AUTOSAR XML (schema 4-3-0)
package /Comp_FDC_ARPkg
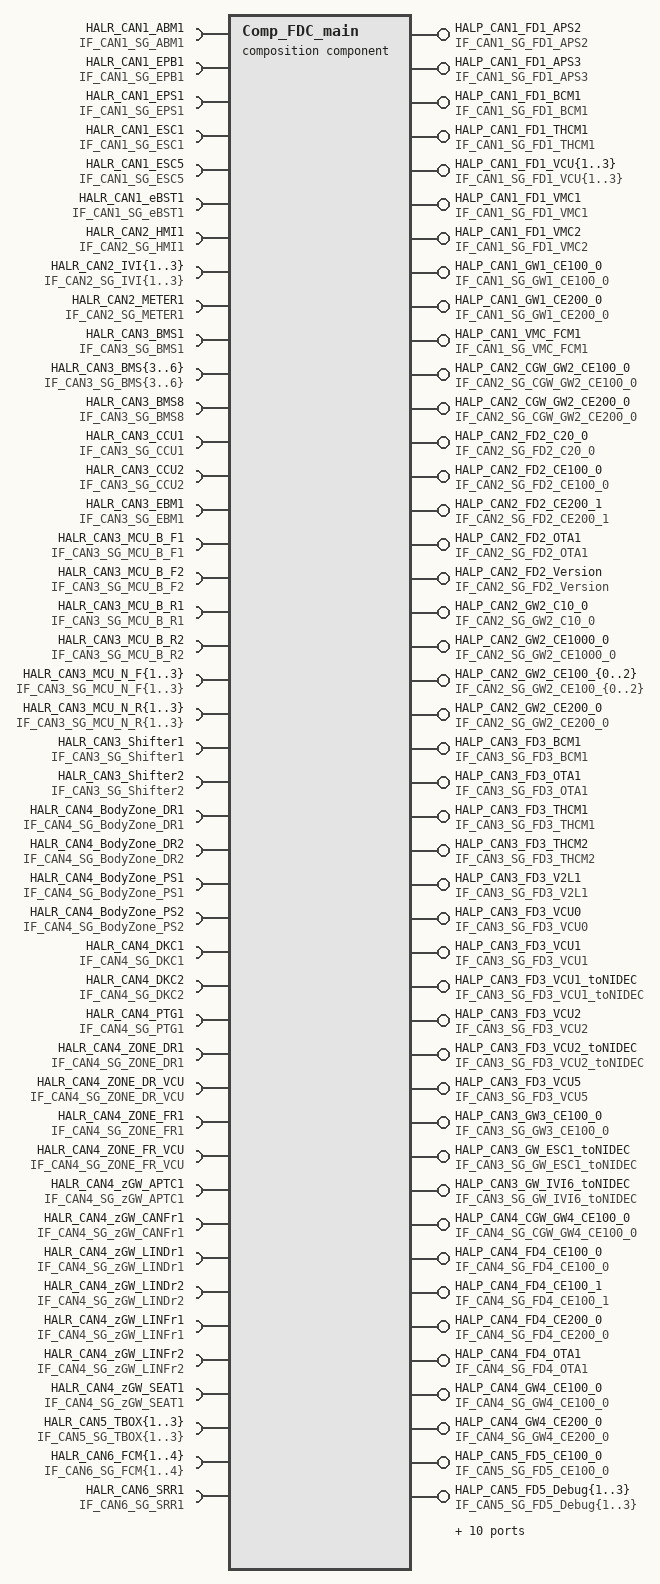
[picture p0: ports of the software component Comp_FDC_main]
  composition sw component type Comp_FDC_main
    58 x require port:
      HALR_CAN1_ABM1: nonqueued-receiver-com-spec{data-element=CAN1_SG_ABM1, handle-out-of-range=DEFAULT, enable-update=true, init-value=constant-reference=Init_CAN1_SG_ABM1}, required-interface=IF_CAN1_SG_ABM1
      HALR_CAN1_EPB1: nonqueued-receiver-com-spec{data-element=CAN1_SG_EPB1, handle-out-of-range=DEFAULT, enable-update=true, init-value=constant-reference=Init_CAN1_SG_EPB1}, required-interface=IF_CAN1_SG_EPB1
      HALR_CAN1_EPS1: nonqueued-receiver-com-spec{data-element=CAN1_SG_EPS1, handle-out-of-range=DEFAULT, enable-update=true, init-value=constant-reference=Init_CAN1_SG_EPS1}, required-interface=IF_CAN1_SG_EPS1
      HALR_CAN1_ESC1: nonqueued-receiver-com-spec{data-element=CAN1_SG_ESC1, handle-out-of-range=DEFAULT, enable-update=true, init-value=constant-reference=Init_CAN1_SG_ESC1}, required-interface=IF_CAN1_SG_ESC1
      HALR_CAN1_ESC5: nonqueued-receiver-com-spec{data-element=CAN1_SG_ESC5, handle-out-of-range=DEFAULT, enable-update=true, init-value=constant-reference=Init_CAN1_SG_ESC5}, required-interface=IF_CAN1_SG_ESC5
      HALR_CAN1_eBST1: nonqueued-receiver-com-spec{data-element=CAN1_SG_eBST1, handle-out-of-range=DEFAULT, enable-update=true, init-value=constant-reference=Init_CAN1_SG_eBST1}, required-interface=IF_CAN1_SG_eBST1
      HALR_CAN2_HMI1: nonqueued-receiver-com-spec{data-element=CAN2_SG_HMI1, handle-out-of-range=DEFAULT, enable-update=true, init-value=constant-reference=Init_CAN2_SG_HMI1}, required-interface=IF_CAN2_SG_HMI1
      HALR_CAN2_IVI{1..3}: nonqueued-receiver-com-spec{data-element=CAN2_SG_IVI{1..3}, handle-out-of-range=DEFAULT, enable-update=true, init-value=constant-reference=Init_CAN2_SG_IVI{1..3}}, required-interface=IF_CAN2_SG_IVI{1..3}
      HALR_CAN2_METER1: nonqueued-receiver-com-spec{data-element=CAN2_SG_METER1, handle-out-of-range=DEFAULT, enable-update=true, init-value=constant-reference=Init_CAN2_SG_METER1}, required-interface=IF_CAN2_SG_METER1
      HALR_CAN3_BMS1: nonqueued-receiver-com-spec{data-element=CAN3_SG_BMS1, handle-out-of-range=DEFAULT, enable-update=true, init-value=constant-reference=Init_CAN3_SG_BMS1}, required-interface=IF_CAN3_SG_BMS1
      HALR_CAN3_BMS{3..6}: nonqueued-receiver-com-spec{data-element=CAN3_SG_BMS{3..6}, handle-out-of-range=DEFAULT, enable-update=true, init-value=constant-reference=Init_CAN3_SG_BMS{3..6}}, required-interface=IF_CAN3_SG_BMS{3..6}
      HALR_CAN3_BMS8: nonqueued-receiver-com-spec{data-element=CAN3_SG_BMS8, handle-out-of-range=DEFAULT, enable-update=true, init-value=constant-reference=Init_CAN3_SG_BMS8}, required-interface=IF_CAN3_SG_BMS8
      HALR_CAN3_CCU1: nonqueued-receiver-com-spec{data-element=CAN3_SG_CCU1, handle-out-of-range=DEFAULT, enable-update=true, init-value=constant-reference=Init_CAN3_SG_CCU1}, required-interface=IF_CAN3_SG_CCU1
      HALR_CAN3_CCU2: nonqueued-receiver-com-spec{data-element=CAN3_SG_CCU2, handle-out-of-range=DEFAULT, enable-update=true, init-value=constant-reference=Init_CAN3_SG_CCU2}, required-interface=IF_CAN3_SG_CCU2
      HALR_CAN3_EBM1: nonqueued-receiver-com-spec{data-element=CAN3_SG_EBM1, handle-out-of-range=DEFAULT, enable-update=true, init-value=constant-reference=Init_CAN3_SG_EBM1}, required-interface=IF_CAN3_SG_EBM1
      HALR_CAN3_MCU_B_F1: nonqueued-receiver-com-spec{data-element=CAN3_SG_MCU_B_F1, handle-out-of-range=DEFAULT, enable-update=true, init-value=constant-reference=Init_CAN3_SG_MCU_B_F1}, required-interface=IF_CAN3_SG_MCU_B_F1
      HALR_CAN3_MCU_B_F2: nonqueued-receiver-com-spec{data-element=CAN3_SG_MCU_B_F2, handle-out-of-range=DEFAULT, enable-update=true, init-value=constant-reference=Init_CAN3_SG_MCU_B_F2}, required-interface=IF_CAN3_SG_MCU_B_F2
      HALR_CAN3_MCU_B_R1: nonqueued-receiver-com-spec{data-element=CAN3_SG_MCU_B_R1, handle-out-of-range=DEFAULT, enable-update=true, init-value=constant-reference=Init_CAN3_SG_MCU_B_R1}, required-interface=IF_CAN3_SG_MCU_B_R1
      HALR_CAN3_MCU_B_R2: nonqueued-receiver-com-spec{data-element=CAN3_SG_MCU_B_R2, handle-out-of-range=DEFAULT, enable-update=true, init-value=constant-reference=Init_CAN3_SG_MCU_B_R2}, required-interface=IF_CAN3_SG_MCU_B_R2
      HALR_CAN3_MCU_N_F{1..3}: nonqueued-receiver-com-spec{data-element=CAN3_SG_MCU_N_F{1..3}, handle-out-of-range=DEFAULT, enable-update=true, init-value=constant-reference=Init_CAN3_SG_MCU_N_F{1..3}}, required-interface=IF_CAN3_SG_MCU_N_F{1..3}
      HALR_CAN3_MCU_N_R{1..3}: nonqueued-receiver-com-spec{data-element=CAN3_SG_MCU_N_R{1..3}, handle-out-of-range=DEFAULT, enable-update=true, init-value=constant-reference=Init_CAN3_SG_MCU_N_R{1..3}}, required-interface=IF_CAN3_SG_MCU_N_R{1..3}
      HALR_CAN3_Shifter1: nonqueued-receiver-com-spec{data-element=CAN3_SG_Shifter1, handle-out-of-range=DEFAULT, enable-update=true, init-value=constant-reference=Init_CAN3_SG_Shifter1}, required-interface=IF_CAN3_SG_Shifter1
      HALR_CAN3_Shifter2: nonqueued-receiver-com-spec{data-element=CAN3_SG_Shifter2, handle-out-of-range=DEFAULT, enable-update=true, init-value=constant-reference=Init_CAN3_SG_Shifter2}, required-interface=IF_CAN3_SG_Shifter2
      HALR_CAN4_BodyZone_DR1: nonqueued-receiver-com-spec{data-element=CAN4_SG_BodyZone_DR1, handle-out-of-range=DEFAULT, enable-update=true, init-value=constant-reference=Init_CAN4_SG_BodyZone_DR1}, required-interface=IF_CAN4_SG_BodyZone_DR1
      HALR_CAN4_BodyZone_DR2: nonqueued-receiver-com-spec{data-element=CAN4_SG_BodyZone_DR2, handle-out-of-range=DEFAULT, enable-update=true, init-value=constant-reference=Init_CAN4_SG_BodyZone_DR2}, required-interface=IF_CAN4_SG_BodyZone_DR2
      HALR_CAN4_BodyZone_PS1: nonqueued-receiver-com-spec{data-element=CAN4_SG_BodyZone_PS1, handle-out-of-range=DEFAULT, enable-update=true, init-value=constant-reference=Init_CAN4_SG_BodyZone_PS1}, required-interface=IF_CAN4_SG_BodyZone_PS1
      HALR_CAN4_BodyZone_PS2: nonqueued-receiver-com-spec{data-element=CAN4_SG_BodyZone_PS2, handle-out-of-range=DEFAULT, enable-update=true, init-value=constant-reference=Init_CAN4_SG_BodyZone_PS2}, required-interface=IF_CAN4_SG_BodyZone_PS2
      HALR_CAN4_DKC1: nonqueued-receiver-com-spec{data-element=CAN4_SG_DKC1, handle-out-of-range=DEFAULT, enable-update=true, init-value=constant-reference=Init_CAN4_SG_DKC1}, required-interface=IF_CAN4_SG_DKC1
      HALR_CAN4_DKC2: nonqueued-receiver-com-spec{data-element=CAN4_SG_DKC2, handle-out-of-range=DEFAULT, enable-update=true, init-value=constant-reference=Init_CAN4_SG_DKC2}, required-interface=IF_CAN4_SG_DKC2
      HALR_CAN4_PTG1: nonqueued-receiver-com-spec{data-element=CAN4_SG_PTG1, handle-out-of-range=DEFAULT, enable-update=true, init-value=constant-reference=Init_CAN4_SG_PTG1}, required-interface=IF_CAN4_SG_PTG1
      HALR_CAN4_ZONE_DR1: nonqueued-receiver-com-spec{data-element=CAN4_SG_ZONE_DR1, handle-out-of-range=DEFAULT, enable-update=true, init-value=constant-reference=Init_CAN4_SG_ZONE_DR1}, required-interface=IF_CAN4_SG_ZONE_DR1
      HALR_CAN4_ZONE_DR_VCU: nonqueued-receiver-com-spec{data-element=CAN4_SG_ZONE_DR_VCU, handle-out-of-range=DEFAULT, enable-update=true, init-value=constant-reference=Init_CAN4_SG_ZONE_DR_VCU}, required-interface=IF_CAN4_SG_ZONE_DR_VCU
      HALR_CAN4_ZONE_FR1: nonqueued-receiver-com-spec{data-element=CAN4_SG_ZONE_FR1, handle-out-of-range=DEFAULT, enable-update=true, init-value=constant-reference=Init_CAN4_SG_ZONE_FR1}, required-interface=IF_CAN4_SG_ZONE_FR1
      HALR_CAN4_ZONE_FR_VCU: nonqueued-receiver-com-spec{data-element=CAN4_SG_ZONE_FR_VCU, handle-out-of-range=DEFAULT, enable-update=true, init-value=constant-reference=Init_CAN4_SG_ZONE_FR_VCU}, required-interface=IF_CAN4_SG_ZONE_FR_VCU
      HALR_CAN4_zGW_APTC1: nonqueued-receiver-com-spec{data-element=CAN4_SG_zGW_APTC1, handle-out-of-range=DEFAULT, enable-update=true, init-value=constant-reference=Init_CAN4_SG_zGW_APTC1}, required-interface=IF_CAN4_SG_zGW_APTC1
      HALR_CAN4_zGW_CANFr1: nonqueued-receiver-com-spec{data-element=CAN4_SG_zGW_CANFr1, handle-out-of-range=DEFAULT, enable-update=true, init-value=constant-reference=Init_CAN4_SG_zGW_CANFr1}, required-interface=IF_CAN4_SG_zGW_CANFr1
      HALR_CAN4_zGW_LINDr1: nonqueued-receiver-com-spec{data-element=CAN4_SG_zGW_LINDr1, handle-out-of-range=DEFAULT, enable-update=true, init-value=constant-reference=Init_CAN4_SG_zGW_LINDr1}, required-interface=IF_CAN4_SG_zGW_LINDr1
      HALR_CAN4_zGW_LINDr2: nonqueued-receiver-com-spec{data-element=CAN4_SG_zGW_LINDr2, handle-out-of-range=DEFAULT, enable-update=true, init-value=constant-reference=Init_CAN4_SG_zGW_LINDr2}, required-interface=IF_CAN4_SG_zGW_LINDr2
      HALR_CAN4_zGW_LINFr1: nonqueued-receiver-com-spec{data-element=CAN4_SG_zGW_LINFr1, handle-out-of-range=DEFAULT, enable-update=true, init-value=constant-reference=Init_CAN4_SG_zGW_LINFr1}, required-interface=IF_CAN4_SG_zGW_LINFr1
      HALR_CAN4_zGW_LINFr2: nonqueued-receiver-com-spec{data-element=CAN4_SG_zGW_LINFr2, handle-out-of-range=DEFAULT, enable-update=true, init-value=constant-reference=Init_CAN4_SG_zGW_LINFr2}, required-interface=IF_CAN4_SG_zGW_LINFr2
      HALR_CAN4_zGW_SEAT1: nonqueued-receiver-com-spec{data-element=CAN4_SG_zGW_SEAT1, handle-out-of-range=DEFAULT, enable-update=true, init-value=constant-reference=Init_CAN4_SG_zGW_SEAT1}, required-interface=IF_CAN4_SG_zGW_SEAT1
      HALR_CAN5_TBOX{1..3}: nonqueued-receiver-com-spec{data-element=CAN5_SG_TBOX{1..3}, handle-out-of-range=DEFAULT, enable-update=true, init-value=constant-reference=Init_CAN5_SG_TBOX{1..3}}, required-interface=IF_CAN5_SG_TBOX{1..3}
      HALR_CAN6_FCM{1..4}: nonqueued-receiver-com-spec{data-element=CAN6_SG_FCM{1..4}, handle-out-of-range=DEFAULT, enable-update=true, init-value=constant-reference=Init_CAN6_SG_FCM{1..4}}, required-interface=IF_CAN6_SG_FCM{1..4}
      HALR_CAN6_SRR1: nonqueued-receiver-com-spec{data-element=CAN6_SG_SRR1, handle-out-of-range=DEFAULT, enable-update=true, init-value=constant-reference=Init_CAN6_SG_SRR1}, required-interface=IF_CAN6_SG_SRR1
    60 x provide port:
      HALP_CAN1_FD1_APS2: nonqueued-sender-com-spec{data-element=CAN1_SG_FD1_APS2, handle-out-of-range=DEFAULT, init-value=constant-reference=Init_CAN1_SG_FD1_APS2}, provided-interface=IF_CAN1_SG_FD1_APS2
      HALP_CAN1_FD1_APS3: nonqueued-sender-com-spec{data-element=CAN1_SG_FD1_APS3, handle-out-of-range=DEFAULT, init-value=constant-reference=Init_CAN1_SG_FD1_APS3}, provided-interface=IF_CAN1_SG_FD1_APS3
      HALP_CAN1_FD1_BCM1: nonqueued-sender-com-spec{data-element=CAN1_SG_FD1_BCM1, handle-out-of-range=DEFAULT, init-value=constant-reference=Init_CAN1_SG_FD1_BCM1}, provided-interface=IF_CAN1_SG_FD1_BCM1
      HALP_CAN1_FD1_THCM1: nonqueued-sender-com-spec{data-element=CAN1_SG_FD1_THCM1, handle-out-of-range=DEFAULT, init-value=constant-reference=Init_CAN1_SG_FD1_THCM1}, provided-interface=IF_CAN1_SG_FD1_THCM1
      HALP_CAN1_FD1_VCU{1..3}: nonqueued-sender-com-spec{data-element=CAN1_SG_FD1_VCU{1..3}, handle-out-of-range=DEFAULT, init-value=constant-reference=Init_CAN1_SG_FD1_VCU{1..3}}, provided-interface=IF_CAN1_SG_FD1_VCU{1..3}
      HALP_CAN1_FD1_VMC1: nonqueued-sender-com-spec{data-element=CAN1_SG_FD1_VMC1, handle-out-of-range=DEFAULT, init-value=constant-reference=Init_CAN1_SG_FD1_VMC1}, provided-interface=IF_CAN1_SG_FD1_VMC1
      HALP_CAN1_FD1_VMC2: nonqueued-sender-com-spec{data-element=CAN1_SG_FD1_VMC2, handle-out-of-range=DEFAULT, init-value=constant-reference=Init_CAN1_SG_FD1_VMC2}, provided-interface=IF_CAN1_SG_FD1_VMC2
      HALP_CAN1_GW1_CE100_0: nonqueued-sender-com-spec{data-element=CAN1_SG_GW1_CE100_0, handle-out-of-range=DEFAULT, init-value=constant-reference=Init_CAN1_SG_GW1_CE100_0}, provided-interface=IF_CAN1_SG_GW1_CE100_0
      HALP_CAN1_GW1_CE200_0: nonqueued-sender-com-spec{data-element=CAN1_SG_GW1_CE200_0, handle-out-of-range=DEFAULT, init-value=constant-reference=Init_CAN1_SG_GW1_CE200_0}, provided-interface=IF_CAN1_SG_GW1_CE200_0
      HALP_CAN1_VMC_FCM1: nonqueued-sender-com-spec{data-element=CAN1_SG_VMC_FCM1, handle-out-of-range=DEFAULT, init-value=constant-reference=Init_CAN1_SG_VMC_FCM1}, provided-interface=IF_CAN1_SG_VMC_FCM1
      HALP_CAN2_CGW_GW2_CE100_0: nonqueued-sender-com-spec{data-element=CAN2_SG_CGW_GW2_CE100_0, handle-out-of-range=DEFAULT, init-value=constant-reference=Init_CAN2_SG_CGW_GW2_CE100_0}, provided-interface=IF_CAN2_SG_CGW_GW2_CE100_0
      HALP_CAN2_CGW_GW2_CE200_0: nonqueued-sender-com-spec{data-element=CAN2_SG_CGW_GW2_CE200_0, handle-out-of-range=DEFAULT, init-value=constant-reference=Init_CAN2_SG_CGW_GW2_CE200_0}, provided-interface=IF_CAN2_SG_CGW_GW2_CE200_0
      HALP_CAN2_FD2_C20_0: nonqueued-sender-com-spec{data-element=CAN2_SG_FD2_C20_0, handle-out-of-range=DEFAULT, init-value=constant-reference=Init_CAN2_SG_FD2_C20_0}, provided-interface=IF_CAN2_SG_FD2_C20_0
      HALP_CAN2_FD2_CE100_0: nonqueued-sender-com-spec{data-element=CAN2_SG_FD2_CE100_0, handle-out-of-range=DEFAULT, init-value=constant-reference=Init_CAN2_SG_FD2_CE100_0}, provided-interface=IF_CAN2_SG_FD2_CE100_0
      HALP_CAN2_FD2_CE200_1: nonqueued-sender-com-spec{data-element=CAN2_SG_FD2_CE200_1, handle-out-of-range=DEFAULT, init-value=constant-reference=Init_CAN2_SG_FD2_CE200_1}, provided-interface=IF_CAN2_SG_FD2_CE200_1
      HALP_CAN2_FD2_OTA1: nonqueued-sender-com-spec{data-element=CAN2_SG_FD2_OTA1, handle-out-of-range=DEFAULT, init-value=constant-reference=Init_CAN2_SG_FD2_OTA1}, provided-interface=IF_CAN2_SG_FD2_OTA1
      HALP_CAN2_FD2_Version: nonqueued-sender-com-spec{data-element=CAN2_SG_FD2_Version, handle-out-of-range=DEFAULT, init-value=constant-reference=Init_CAN2_SG_FD2_Version}, provided-interface=IF_CAN2_SG_FD2_Version
      HALP_CAN2_GW2_C10_0: nonqueued-sender-com-spec{data-element=CAN2_SG_GW2_C10_0, handle-out-of-range=DEFAULT, init-value=constant-reference=Init_CAN2_SG_GW2_C10_0}, provided-interface=IF_CAN2_SG_GW2_C10_0
      HALP_CAN2_GW2_CE1000_0: nonqueued-sender-com-spec{data-element=CAN2_SG_GW2_CE1000_0, handle-out-of-range=DEFAULT, init-value=constant-reference=Init_CAN2_SG_GW2_CE1000_0}, provided-interface=IF_CAN2_SG_GW2_CE1000_0
      HALP_CAN2_GW2_CE100_{0..2}: nonqueued-sender-com-spec{data-element=CAN2_SG_GW2_CE100_{0..2}, handle-out-of-range=DEFAULT, init-value=constant-reference=Init_CAN2_SG_GW2_CE100_{0..2}}, provided-interface=IF_CAN2_SG_GW2_CE100_{0..2}
      HALP_CAN2_GW2_CE200_0: nonqueued-sender-com-spec{data-element=CAN2_SG_GW2_CE200_0, handle-out-of-range=DEFAULT, init-value=constant-reference=Init_CAN2_SG_GW2_CE200_0}, provided-interface=IF_CAN2_SG_GW2_CE200_0
      HALP_CAN3_FD3_BCM1: nonqueued-sender-com-spec{data-element=CAN3_SG_FD3_BCM1, handle-out-of-range=DEFAULT, init-value=constant-reference=Init_CAN3_SG_FD3_BCM1}, provided-interface=IF_CAN3_SG_FD3_BCM1
      HALP_CAN3_FD3_OTA1: nonqueued-sender-com-spec{data-element=CAN3_SG_FD3_OTA1, handle-out-of-range=DEFAULT, init-value=constant-reference=Init_CAN3_SG_FD3_OTA1}, provided-interface=IF_CAN3_SG_FD3_OTA1
      HALP_CAN3_FD3_THCM1: nonqueued-sender-com-spec{data-element=CAN3_SG_FD3_THCM1, handle-out-of-range=DEFAULT, init-value=constant-reference=Init_CAN3_SG_FD3_THCM1}, provided-interface=IF_CAN3_SG_FD3_THCM1
      HALP_CAN3_FD3_THCM2: nonqueued-sender-com-spec{data-element=CAN3_SG_FD3_THCM2, handle-out-of-range=DEFAULT, init-value=constant-reference=Init_CAN3_SG_FD3_THCM2}, provided-interface=IF_CAN3_SG_FD3_THCM2
      HALP_CAN3_FD3_V2L1: nonqueued-sender-com-spec{data-element=CAN3_SG_FD3_V2L1, handle-out-of-range=DEFAULT, init-value=constant-reference=Init_CAN3_SG_FD3_V2L1}, provided-interface=IF_CAN3_SG_FD3_V2L1
      HALP_CAN3_FD3_VCU0: nonqueued-sender-com-spec{data-element=CAN3_SG_FD3_VCU0, handle-out-of-range=DEFAULT, init-value=constant-reference=Init_CAN3_SG_FD3_VCU0}, provided-interface=IF_CAN3_SG_FD3_VCU0
      HALP_CAN3_FD3_VCU1: nonqueued-sender-com-spec{data-element=CAN3_SG_FD3_VCU1, handle-out-of-range=DEFAULT, init-value=constant-reference=Init_CAN3_SG_FD3_VCU1}, provided-interface=IF_CAN3_SG_FD3_VCU1
      HALP_CAN3_FD3_VCU1_toNIDEC: nonqueued-sender-com-spec{data-element=CAN3_SG_FD3_VCU1_toNIDEC, handle-out-of-range=DEFAULT, init-value=constant-reference=Init_CAN3_SG_FD3_VCU1_toNIDEC}, provided-interface=IF_CAN3_SG_FD3_VCU1_toNIDEC
      HALP_CAN3_FD3_VCU2: nonqueued-sender-com-spec{data-element=CAN3_SG_FD3_VCU2, handle-out-of-range=DEFAULT, init-value=constant-reference=Init_CAN3_SG_FD3_VCU2}, provided-interface=IF_CAN3_SG_FD3_VCU2
      HALP_CAN3_FD3_VCU2_toNIDEC: nonqueued-sender-com-spec{data-element=CAN3_SG_FD3_VCU2_toNIDEC, handle-out-of-range=DEFAULT, init-value=constant-reference=Init_CAN3_SG_FD3_VCU2_toNIDEC}, provided-interface=IF_CAN3_SG_FD3_VCU2_toNIDEC
      HALP_CAN3_FD3_VCU5: nonqueued-sender-com-spec{data-element=CAN3_SG_FD3_VCU5, handle-out-of-range=DEFAULT, init-value=constant-reference=Init_CAN3_SG_FD3_VCU5}, provided-interface=IF_CAN3_SG_FD3_VCU5
      HALP_CAN3_GW3_CE100_0: nonqueued-sender-com-spec{data-element=CAN3_SG_GW3_CE100_0, handle-out-of-range=DEFAULT, init-value=constant-reference=Init_CAN3_SG_GW3_CE100_0}, provided-interface=IF_CAN3_SG_GW3_CE100_0
      HALP_CAN3_GW_ESC1_toNIDEC: nonqueued-sender-com-spec{data-element=CAN3_SG_GW_ESC1_toNIDEC, handle-out-of-range=DEFAULT, init-value=constant-reference=Init_CAN3_SG_GW_ESC1_toNIDEC}, provided-interface=IF_CAN3_SG_GW_ESC1_toNIDEC
      HALP_CAN3_GW_IVI6_toNIDEC: nonqueued-sender-com-spec{data-element=CAN3_SG_GW_IVI6_toNIDEC, handle-out-of-range=DEFAULT, init-value=constant-reference=Init_CAN3_SG_GW_IVI6_toNIDEC}, provided-interface=IF_CAN3_SG_GW_IVI6_toNIDEC
      HALP_CAN4_CGW_GW4_CE100_0: nonqueued-sender-com-spec{data-element=CAN4_SG_CGW_GW4_CE100_0, handle-out-of-range=DEFAULT, init-value=constant-reference=Init_CAN4_SG_CGW_GW4_CE100_0}, provided-interface=IF_CAN4_SG_CGW_GW4_CE100_0
      HALP_CAN4_FD4_CE100_0: nonqueued-sender-com-spec{data-element=CAN4_SG_FD4_CE100_0, handle-out-of-range=DEFAULT, init-value=constant-reference=Init_CAN4_SG_FD4_CE100_0}, provided-interface=IF_CAN4_SG_FD4_CE100_0
      HALP_CAN4_FD4_CE100_1: nonqueued-sender-com-spec{data-element=CAN4_SG_FD4_CE100_1, handle-out-of-range=DEFAULT, init-value=constant-reference=Init_CAN4_SG_FD4_CE100_1}, provided-interface=IF_CAN4_SG_FD4_CE100_1
      HALP_CAN4_FD4_CE200_0: nonqueued-sender-com-spec{data-element=CAN4_SG_FD4_CE200_0, handle-out-of-range=DEFAULT, init-value=constant-reference=Init_CAN4_SG_FD4_CE200_0}, provided-interface=IF_CAN4_SG_FD4_CE200_0
      HALP_CAN4_FD4_OTA1: nonqueued-sender-com-spec{data-element=CAN4_SG_FD4_OTA1, handle-out-of-range=DEFAULT, init-value=constant-reference=Init_CAN4_SG_FD4_OTA1}, provided-interface=IF_CAN4_SG_FD4_OTA1
      HALP_CAN4_GW4_CE100_0: nonqueued-sender-com-spec{data-element=CAN4_SG_GW4_CE100_0, handle-out-of-range=DEFAULT, init-value=constant-reference=Init_CAN4_SG_GW4_CE100_0}, provided-interface=IF_CAN4_SG_GW4_CE100_0
      HALP_CAN4_GW4_CE200_0: nonqueued-sender-com-spec{data-element=CAN4_SG_GW4_CE200_0, handle-out-of-range=DEFAULT, init-value=constant-reference=Init_CAN4_SG_GW4_CE200_0}, provided-interface=IF_CAN4_SG_GW4_CE200_0
      HALP_CAN5_FD5_CE100_0: nonqueued-sender-com-spec{data-element=CAN5_SG_FD5_CE100_0, handle-out-of-range=DEFAULT, init-value=constant-reference=Init_CAN5_SG_FD5_CE100_0}, provided-interface=IF_CAN5_SG_FD5_CE100_0
      HALP_CAN5_FD5_Debug{1..3}: nonqueued-sender-com-spec{data-element=CAN5_SG_FD5_Debug{1..3}, handle-out-of-range=DEFAULT, init-value=constant-reference=Init_CAN5_SG_FD5_Debug{1..3}}, provided-interface=IF_CAN5_SG_FD5_Debug{1..3}
      HALP_CAN5_FD5_OTA1: nonqueued-sender-com-spec{data-element=CAN5_SG_FD5_OTA1, handle-out-of-range=DEFAULT, init-value=constant-reference=Init_CAN5_SG_FD5_OTA1}, provided-interface=IF_CAN5_SG_FD5_OTA1
      HALP_CAN5_GW5_CE100_0: nonqueued-sender-com-spec{data-element=CAN5_SG_GW5_CE100_0, handle-out-of-range=DEFAULT, init-value=constant-reference=Init_CAN5_SG_GW5_CE100_0}, provided-interface=IF_CAN5_SG_GW5_CE100_0
      HALP_CAN6_CGW_GW6_CE100_0: nonqueued-sender-com-spec{data-element=CAN6_SG_CGW_GW6_CE100_0, handle-out-of-range=DEFAULT, init-value=constant-reference=Init_CAN6_SG_CGW_GW6_CE100_0}, provided-interface=IF_CAN6_SG_CGW_GW6_CE100_0
      HALP_CAN6_FD6_APS3: nonqueued-sender-com-spec{data-element=CAN6_SG_FD6_APS3, handle-out-of-range=DEFAULT, init-value=constant-reference=Init_CAN6_SG_FD6_APS3}, provided-interface=IF_CAN6_SG_FD6_APS3
      HALP_CAN6_FD6_BCM1: nonqueued-sender-com-spec{data-element=CAN6_SG_FD6_BCM1, handle-out-of-range=DEFAULT, init-value=constant-reference=Init_CAN6_SG_FD6_BCM1}, provided-interface=IF_CAN6_SG_FD6_BCM1
      HALP_CAN6_FD6_VCU1: nonqueued-sender-com-spec{data-element=CAN6_SG_FD6_VCU1, handle-out-of-range=DEFAULT, init-value=constant-reference=Init_CAN6_SG_FD6_VCU1}, provided-interface=IF_CAN6_SG_FD6_VCU1
      HALP_CAN6_FD6_VCU2: nonqueued-sender-com-spec{data-element=CAN6_SG_FD6_VCU2, handle-out-of-range=DEFAULT, init-value=constant-reference=Init_CAN6_SG_FD6_VCU2}, provided-interface=IF_CAN6_SG_FD6_VCU2
      HALP_CAN6_FD6_VMC1: nonqueued-sender-com-spec{data-element=CAN6_SG_FD6_VMC1, handle-out-of-range=DEFAULT, init-value=constant-reference=Init_CAN6_SG_FD6_VMC1}, provided-interface=IF_CAN6_SG_FD6_VMC1
      HALP_CAN6_GW6_CE100_0: nonqueued-sender-com-spec{data-element=CAN6_SG_GW6_CE100_0, handle-out-of-range=DEFAULT, init-value=constant-reference=Init_CAN6_SG_GW6_CE100_0}, provided-interface=IF_CAN6_SG_GW6_CE100_0
      HALP_CAN7_GW7_C100_0: nonqueued-sender-com-spec{data-element=CAN7_SG_GW7_C100_0, handle-out-of-range=DEFAULT, init-value=constant-reference=Init_CAN7_SG_GW7_C100_0}, provided-interface=IF_CAN7_SG_GW7_C100_0
    12 x component:
      BswMTest: type=BswMTest_type
      SWC_APS: type=SWC_APS_type
      SWC_CDD: type=SWC_CDD_type
      SWC_DID: type=SWC_DID_type
      SWC_FDC: type=SWC_FDC_type
      SWC_IMU: type=SWC_IMU_type
      SWC_LOG: type=SWC_LOG_type
      SWC_NVM: type=SWC_NVM_type
      SWC_UART: type=SWC_UART_type
      SWC_VES: type=SWC_VES_type
      SWC_UDS: type=SWC_UDS_type
      SWC_CGW: type=SWC_CGW_type
    delegate SWC_FDC.R_CAN1_ABM1 <-> outer port HALR_CAN1_ABM1
    delegate SWC_FDC.R_CAN1_EPB1 <-> outer port HALR_CAN1_EPB1
    delegate SWC_FDC.R_CAN1_EPS1 <-> outer port HALR_CAN1_EPS1
    delegate SWC_FDC.R_CAN1_ESC1 <-> outer port HALR_CAN1_ESC1
    delegate SWC_FDC.R_CAN1_ESC5 <-> outer port HALR_CAN1_ESC5
    delegate SWC_FDC.R_CAN1_eBST1 <-> outer port HALR_CAN1_eBST1
    delegate SWC_FDC.R_CAN2_HMI1 <-> outer port HALR_CAN2_HMI1
    delegate SWC_FDC.R_CAN2_IVI{1..3} <-> outer port HALR_CAN2_IVI{1..3}
    delegate SWC_FDC.R_CAN2_METER1 <-> outer port HALR_CAN2_METER1
    delegate SWC_FDC.R_CAN3_BMS1 <-> outer port HALR_CAN3_BMS1
    delegate SWC_FDC.R_CAN3_BMS{3..6} <-> outer port HALR_CAN3_BMS{3..6}
    delegate SWC_FDC.R_CAN3_BMS8 <-> outer port HALR_CAN3_BMS8
    delegate SWC_FDC.R_CAN3_CCU1 <-> outer port HALR_CAN3_CCU1
    delegate SWC_FDC.R_CAN3_CCU2 <-> outer port HALR_CAN3_CCU2
    delegate SWC_FDC.R_CAN3_EBM1 <-> outer port HALR_CAN3_EBM1
    delegate SWC_FDC.R_CAN3_MCU_B_F1 <-> outer port HALR_CAN3_MCU_B_F1
    delegate SWC_FDC.R_CAN3_MCU_B_F2 <-> outer port HALR_CAN3_MCU_B_F2
    delegate SWC_FDC.R_CAN3_MCU_B_R1 <-> outer port HALR_CAN3_MCU_B_R1
    delegate SWC_FDC.R_CAN3_MCU_B_R2 <-> outer port HALR_CAN3_MCU_B_R2
    delegate SWC_FDC.R_CAN3_MCU_N_F{1..3} <-> outer port HALR_CAN3_MCU_N_F{1..3}
    delegate SWC_FDC.R_CAN3_MCU_N_R{1..3} <-> outer port HALR_CAN3_MCU_N_R{1..3}
    delegate SWC_FDC.R_CAN3_Shifter1 <-> outer port HALR_CAN3_Shifter1
    delegate SWC_FDC.R_CAN3_Shifter2 <-> outer port HALR_CAN3_Shifter2
    delegate SWC_FDC.R_CAN4_BodyZone_DR1 <-> outer port HALR_CAN4_BodyZone_DR1
    delegate SWC_FDC.R_CAN4_BodyZone_DR2 <-> outer port HALR_CAN4_BodyZone_DR2
    delegate SWC_FDC.R_CAN4_BodyZone_PS1 <-> outer port HALR_CAN4_BodyZone_PS1
    delegate SWC_FDC.R_CAN4_BodyZone_PS2 <-> outer port HALR_CAN4_BodyZone_PS2
    delegate SWC_FDC.R_CAN4_DKC1 <-> outer port HALR_CAN4_DKC1
    delegate SWC_FDC.R_CAN4_DKC2 <-> outer port HALR_CAN4_DKC2
    delegate SWC_FDC.R_CAN4_PTG1 <-> outer port HALR_CAN4_PTG1
    delegate SWC_FDC.R_CAN4_ZONE_DR1 <-> outer port HALR_CAN4_ZONE_DR1
    delegate SWC_FDC.R_CAN4_ZONE_DR_VCU <-> outer port HALR_CAN4_ZONE_DR_VCU
    delegate SWC_FDC.R_CAN4_ZONE_FR1 <-> outer port HALR_CAN4_ZONE_FR1
    delegate SWC_FDC.R_CAN4_ZONE_FR_VCU <-> outer port HALR_CAN4_ZONE_FR_VCU
    delegate SWC_FDC.R_CAN4_zGW_APTC1 <-> outer port HALR_CAN4_zGW_APTC1
    delegate SWC_FDC.R_CAN4_zGW_CANFr1 <-> outer port HALR_CAN4_zGW_CANFr1
    delegate SWC_FDC.R_CAN4_zGW_LINDr1 <-> outer port HALR_CAN4_zGW_LINDr1
    delegate SWC_FDC.R_CAN4_zGW_LINDr2 <-> outer port HALR_CAN4_zGW_LINDr2
    delegate SWC_FDC.R_CAN4_zGW_LINFr1 <-> outer port HALR_CAN4_zGW_LINFr1
    delegate SWC_FDC.R_CAN4_zGW_LINFr2 <-> outer port HALR_CAN4_zGW_LINFr2
    delegate SWC_FDC.R_CAN4_zGW_SEAT1 <-> outer port HALR_CAN4_zGW_SEAT1
    delegate SWC_FDC.R_CAN5_TBOX{1..3} <-> outer port HALR_CAN5_TBOX{1..3}
    delegate SWC_FDC.R_CAN6_FCM{1..4} <-> outer port HALR_CAN6_FCM{1..4}
    delegate SWC_FDC.R_CAN6_SRR1 <-> outer port HALR_CAN6_SRR1
    delegate SWC_CGW.R_CAN1_ABM1 <-> outer port HALR_CAN1_ABM1
    delegate SWC_CGW.R_CAN1_EPS1 <-> outer port HALR_CAN1_EPS1
    delegate SWC_CGW.R_CAN1_ESC1 <-> outer port HALR_CAN1_ESC1
    delegate SWC_CGW.R_CAN1_ESC5 <-> outer port HALR_CAN1_ESC5
    delegate SWC_CGW.R_CAN1_eBST1 <-> outer port HALR_CAN1_eBST1
    delegate SWC_CGW.R_CAN2_HMI1 <-> outer port HALR_CAN2_HMI1
    delegate SWC_CGW.R_CAN2_IVI{1..3} <-> outer port HALR_CAN2_IVI{1..3}
    delegate SWC_CGW.R_CAN2_METER1 <-> outer port HALR_CAN2_METER1
    delegate SWC_CGW.R_CAN3_BMS1 <-> outer port HALR_CAN3_BMS1
    delegate SWC_CGW.R_CAN3_BMS{3..6} <-> outer port HALR_CAN3_BMS{3..6}
    delegate SWC_CGW.R_CAN3_BMS8 <-> outer port HALR_CAN3_BMS8
    delegate SWC_CGW.R_CAN3_CCU1 <-> outer port HALR_CAN3_CCU1
    delegate SWC_CGW.R_CAN3_CCU2 <-> outer port HALR_CAN3_CCU2
    delegate SWC_CGW.R_CAN3_EBM1 <-> outer port HALR_CAN3_EBM1
    delegate SWC_CGW.R_CAN3_MCU_B_F1 <-> outer port HALR_CAN3_MCU_B_F1
    delegate SWC_CGW.R_CAN3_MCU_B_F2 <-> outer port HALR_CAN3_MCU_B_F2
    delegate SWC_CGW.R_CAN3_MCU_B_R1 <-> outer port HALR_CAN3_MCU_B_R1
    delegate SWC_CGW.R_CAN3_MCU_B_R2 <-> outer port HALR_CAN3_MCU_B_R2
    delegate SWC_CGW.R_CAN3_MCU_N_F{1..3} <-> outer port HALR_CAN3_MCU_N_F{1..3}
    delegate SWC_CGW.R_CAN3_MCU_N_R{1..3} <-> outer port HALR_CAN3_MCU_N_R{1..3}
    delegate SWC_CGW.R_CAN3_Shifter1 <-> outer port HALR_CAN3_Shifter1
    delegate SWC_CGW.R_CAN4_BodyZone_DR1 <-> outer port HALR_CAN4_BodyZone_DR1
    delegate SWC_CGW.R_CAN4_BodyZone_PS1 <-> outer port HALR_CAN4_BodyZone_PS1
    delegate SWC_CGW.R_CAN4_BodyZone_PS2 <-> outer port HALR_CAN4_BodyZone_PS2
    delegate SWC_CGW.R_CAN4_DKC1 <-> outer port HALR_CAN4_DKC1
    delegate SWC_CGW.R_CAN4_PTG1 <-> outer port HALR_CAN4_PTG1
    delegate SWC_CGW.R_CAN4_ZONE_DR1 <-> outer port HALR_CAN4_ZONE_DR1
    delegate SWC_CGW.R_CAN4_ZONE_DR_VCU <-> outer port HALR_CAN4_ZONE_DR_VCU
    delegate SWC_CGW.R_CAN4_ZONE_FR1 <-> outer port HALR_CAN4_ZONE_FR1
    delegate SWC_CGW.R_CAN4_ZONE_FR_VCU <-> outer port HALR_CAN4_ZONE_FR_VCU
    delegate SWC_CGW.R_CAN4_zGW_APTC1 <-> outer port HALR_CAN4_zGW_APTC1
    delegate SWC_CGW.R_CAN4_zGW_CANFr1 <-> outer port HALR_CAN4_zGW_CANFr1
    delegate SWC_CGW.R_CAN4_zGW_LINDr1 <-> outer port HALR_CAN4_zGW_LINDr1
    delegate SWC_CGW.R_CAN4_zGW_SEAT1 <-> outer port HALR_CAN4_zGW_SEAT1
    delegate SWC_CGW.R_CAN5_TBOX1 <-> outer port HALR_CAN5_TBOX1
    delegate SWC_CGW.R_CAN5_TBOX3 <-> outer port HALR_CAN5_TBOX3
    delegate SWC_CGW.R_CAN6_FCM1 <-> outer port HALR_CAN6_FCM1
    delegate SWC_FDC.P_CAN1_FD1_APS2 <-> outer port HALP_CAN1_FD1_APS2
    delegate SWC_FDC.P_CAN1_FD1_APS3 <-> outer port HALP_CAN1_FD1_APS3
    delegate SWC_FDC.P_CAN1_FD1_BCM1 <-> outer port HALP_CAN1_FD1_BCM1
    delegate SWC_FDC.P_CAN1_FD1_THCM1 <-> outer port HALP_CAN1_FD1_THCM1
    delegate SWC_FDC.P_CAN1_FD1_VCU{1..3} <-> outer port HALP_CAN1_FD1_VCU{1..3}
    delegate SWC_FDC.P_CAN1_FD1_VMC1 <-> outer port HALP_CAN1_FD1_VMC1
    delegate SWC_FDC.P_CAN1_FD1_VMC2 <-> outer port HALP_CAN1_FD1_VMC2
    delegate SWC_FDC.P_CAN1_VMC_FCM1 <-> outer port HALP_CAN1_VMC_FCM1
    delegate SWC_FDC.P_CAN2_FD2_C20_0 <-> outer port HALP_CAN2_FD2_C20_0
    delegate SWC_FDC.P_CAN2_FD2_CE100_0 <-> outer port HALP_CAN2_FD2_CE100_0
    delegate SWC_FDC.P_CAN2_FD2_CE200_1 <-> outer port HALP_CAN2_FD2_CE200_1
    delegate SWC_VES.P_CAN2_FD2_OTA1 <-> outer port HALP_CAN2_FD2_OTA1
    delegate SWC_FDC.P_CAN2_FD2_Version <-> outer port HALP_CAN2_FD2_Version
    delegate SWC_FDC.P_CAN2_GW2_CE100_0 <-> outer port HALP_CAN2_GW2_CE100_0
    delegate SWC_FDC.P_CAN2_GW2_CE200_0 <-> outer port HALP_CAN2_GW2_CE200_0
    delegate SWC_FDC.P_CAN3_FD3_BCM1 <-> outer port HALP_CAN3_FD3_BCM1
    delegate SWC_VES.P_CAN3_FD3_OTA1 <-> outer port HALP_CAN3_FD3_OTA1
    delegate SWC_FDC.P_CAN3_FD3_THCM1 <-> outer port HALP_CAN3_FD3_THCM1
    delegate SWC_FDC.P_CAN3_FD3_THCM2 <-> outer port HALP_CAN3_FD3_THCM2
    delegate SWC_FDC.P_CAN3_FD3_V2L1 <-> outer port HALP_CAN3_FD3_V2L1
    delegate SWC_FDC.P_CAN3_FD3_VCU0 <-> outer port HALP_CAN3_FD3_VCU0
    delegate SWC_FDC.P_CAN3_FD3_VCU1 <-> outer port HALP_CAN3_FD3_VCU1
    delegate SWC_FDC.P_CAN3_FD3_VCU1_toNIDEC <-> outer port HALP_CAN3_FD3_VCU1_toNIDEC
    delegate SWC_FDC.P_CAN3_FD3_VCU2 <-> outer port HALP_CAN3_FD3_VCU2
    delegate SWC_FDC.P_CAN3_FD3_VCU2_toNIDEC <-> outer port HALP_CAN3_FD3_VCU2_toNIDEC
    delegate SWC_FDC.P_CAN3_FD3_VCU5 <-> outer port HALP_CAN3_FD3_VCU5
    delegate SWC_FDC.P_CAN3_GW_ESC1_toNIDEC <-> outer port HALP_CAN3_GW_ESC1_toNIDEC
    delegate SWC_FDC.P_CAN3_GW_IVI6_toNIDEC <-> outer port HALP_CAN3_GW_IVI6_toNIDEC
    delegate SWC_FDC.P_CAN4_FD4_CE100_0 <-> outer port HALP_CAN4_FD4_CE100_0
    delegate SWC_FDC.P_CAN4_FD4_CE100_1 <-> outer port HALP_CAN4_FD4_CE100_1
    delegate SWC_FDC.P_CAN4_FD4_CE200_0 <-> outer port HALP_CAN4_FD4_CE200_0
    delegate SWC_VES.P_CAN4_FD4_OTA1 <-> outer port HALP_CAN4_FD4_OTA1
    delegate SWC_FDC.P_CAN4_GW4_CE100_0 <-> outer port HALP_CAN4_GW4_CE100_0
    delegate SWC_FDC.P_CAN5_FD5_CE100_0 <-> outer port HALP_CAN5_FD5_CE100_0
    delegate SWC_FDC.P_CAN5_FD5_Debug{1..3} <-> outer port HALP_CAN5_FD5_Debug{1..3}
    delegate SWC_VES.P_CAN5_FD5_OTA1 <-> outer port HALP_CAN5_FD5_OTA1
    delegate SWC_FDC.P_CAN6_FD6_APS3 <-> outer port HALP_CAN6_FD6_APS3
    delegate SWC_FDC.P_CAN6_FD6_BCM1 <-> outer port HALP_CAN6_FD6_BCM1
    delegate SWC_FDC.P_CAN6_FD6_VCU1 <-> outer port HALP_CAN6_FD6_VCU1
    delegate SWC_FDC.P_CAN6_FD6_VCU2 <-> outer port HALP_CAN6_FD6_VCU2
    delegate SWC_FDC.P_CAN6_FD6_VMC1 <-> outer port HALP_CAN6_FD6_VMC1
    delegate SWC_FDC.P_CAN6_GW6_CE100_0 <-> outer port HALP_CAN6_GW6_CE100_0
    delegate SWC_CGW.P_CAN1_GW1_CE100_0 <-> outer port HALP_CAN1_GW1_CE100_0
    delegate SWC_CGW.P_CAN1_GW1_CE200_0 <-> outer port HALP_CAN1_GW1_CE200_0
    delegate SWC_CGW.P_CAN2_GW2_C10_0 <-> outer port HALP_CAN2_GW2_C10_0
    delegate SWC_CGW.P_CAN2_GW2_CE1000_0 <-> outer port HALP_CAN2_GW2_CE1000_0
    delegate SWC_CGW.P_CAN2_CGW_GW2_CE100_0 <-> outer port HALP_CAN2_CGW_GW2_CE100_0
    delegate SWC_CGW.P_CAN2_GW2_CE100_1 <-> outer port HALP_CAN2_GW2_CE100_1
    delegate SWC_CGW.P_CAN2_GW2_CE100_2 <-> outer port HALP_CAN2_GW2_CE100_2
    delegate SWC_CGW.P_CAN2_CGW_GW2_CE200_0 <-> outer port HALP_CAN2_CGW_GW2_CE200_0
    delegate SWC_CGW.P_CAN3_GW3_CE100_0 <-> outer port HALP_CAN3_GW3_CE100_0
    delegate SWC_CGW.P_CAN4_CGW_GW4_CE100_0 <-> outer port HALP_CAN4_CGW_GW4_CE100_0
    delegate SWC_CGW.P_CAN4_GW4_CE200_0 <-> outer port HALP_CAN4_GW4_CE200_0
    delegate SWC_CGW.P_CAN5_GW5_CE100_0 <-> outer port HALP_CAN5_GW5_CE100_0
    delegate SWC_CGW.P_CAN6_CGW_GW6_CE100_0 <-> outer port HALP_CAN6_CGW_GW6_CE100_0
    delegate SWC_CGW.P_CAN7_GW7_C100_0 <-> outer port HALP_CAN7_GW7_C100_0
    connect SWC_APS.P_HALINCDD_APS -> SWC_FDC.R_HALIN_APS
    connect SWC_APS.P_HALOUTCDD_APS -> SWC_FDC.R_HALOUT_APS
    connect SWC_CDD.P_HALINCDD -> SWC_FDC.R_HALINCDD
    connect SWC_CDD.P_HALINCDD -> SWC_VES.R_HALINCDD
    connect SWC_CDD.P_HALOUTCDD -> SWC_FDC.R_HALOUTCDD
    connect SWC_DID.P_DIDReadCDD -> SWC_FDC.R_DIDReadCDD
    connect SWC_DID.P_DIDWriteCDD -> SWC_FDC.R_DIDWriteCDD
    connect SWC_FDC.P_AppModeReq -> BswMTest.R_AppModeReq
    connect SWC_FDC.P_E2E_CAN3_VCU1 -> SWC_FDC.R_E2E_CAN3_VCU1
    connect SWC_FDC.P_E2E_CAN3_VCU1_toNIDEC -> SWC_FDC.R_E2E_CAN3_VCU1_toNIDEC
    connect SWC_FDC.P_E2E_CAN4_VCU1 -> SWC_FDC.R_E2E_CAN4_VCU1
    connect SWC_FDC.P_FDCDD_Inner -> SWC_FDC.R_FDCCDD_Inner
    connect SWC_FDC.P_NVMReadCDD_Inner -> SWC_FDC.R_NVMReadCDD_Inner
    connect SWC_FDC.P_NVMWriteCDD_Inner -> SWC_FDC.R_NVMWriteCDD_Inner
    connect SWC_FDC.P_NVMWrite -> SWC_NVM.R_WriteNVData
    connect SWC_FDC.P_WDGCDD -> SWC_FDC.R_WDGCDD
    connect SWC_IMU.P_HAINICDD_IMU -> SWC_FDC.R_HALIN_IMU
    connect SWC_NVM.P_ReadNVData -> SWC_FDC.R_NVMRead
    connect SWC_UART.P_UARTCDD -> SWC_UART.R_UARTCDD
    connect SWC_VES.P_VESCDD -> SWC_VES.R_VESCDD
    connect SWC_UDS.P_UDSCDD -> SWC_FDC.R_UDSCDD
